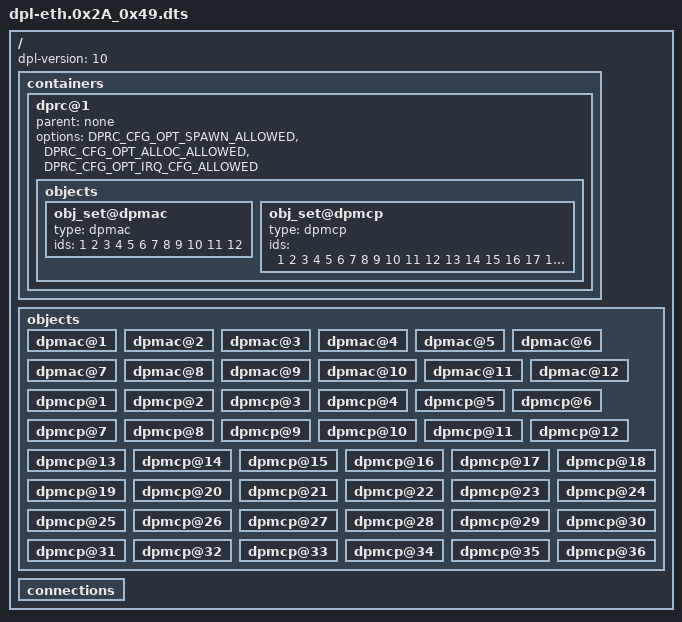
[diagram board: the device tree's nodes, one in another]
/*
 * Copyright 2016 Freescale Semiconductor, Inc.
 */

/dts-v1/;
/ {
	dpl-version = <10>;
	/*****************************************************************
	 * Containers
	 *****************************************************************/
	containers {
		dprc@1 {
			parent = "none";
			options = "DPRC_CFG_OPT_SPAWN_ALLOWED" , "DPRC_CFG_OPT_ALLOC_ALLOWED", "DPRC_CFG_OPT_IRQ_CFG_ALLOWED";

			objects {
				/* ------------- DPMACs --------------*/
				/* For SerDes 0x2a_49, 8 DPMACs are mapped
				 * on the 8 XFI ports and 4 DPMACs
				 * are mapped on the 4 SGMII ports of the PCIe
				 * Slot 4 riser card.
				 */
				obj_set@dpmac {
					type = "dpmac";
					ids = <1 2 3 4 5 6 7 8 9 10 11 12>;
				};

				/* ------------ DPMCPs --------------*/
				/* Ethernet DPMCPs:
				*  One for every DPNI, one for every DPMAC, then
				*  one more for DPIO.
				*
				*  Next: DPRC and restool, VFIO and possibly
				*  others from the kernel have DPMCP requirements.
				*  We'll just add a slack of 10 MCPs.
				*/
				obj_set@dpmcp {
					type = "dpmcp";
					ids = <1 2 3 4 5 6 7 8 9 10 11 12 13 14 15 16 17 18 19 20 21 22 23 24 25 26 27 28 29 30 31 32 33 34 35 36>;
				};
			};
		};
	};

	/*****************************************************************
	 * Objects
	 *****************************************************************/
	objects {
		/* ------------ DPMAC --------------*/
		dpmac@1 {
		};
		dpmac@2 {
		};
		dpmac@3 {
		};
		dpmac@4 {
		};
		dpmac@5 {
		};
		dpmac@6 {
		};
		dpmac@7 {
		};
		dpmac@8 {
		};
		dpmac@9 {
		};
		dpmac@10 {
		};
		dpmac@11 {
		};
		dpmac@12 {
		};

		/* ------------ DPMCP --------------*/
		dpmcp@1 {
		};
		dpmcp@2 {
		};
		dpmcp@3 {
		};
		dpmcp@4 {
		};
		dpmcp@5 {
		};
		dpmcp@6 {
		};
		dpmcp@7 {
		};
		dpmcp@8 {
		};
		dpmcp@9 {
		};
		dpmcp@10 {
		};
		dpmcp@11 {
		};
		dpmcp@12 {
		};
		dpmcp@13 {
		};
		dpmcp@14 {
		};
		dpmcp@15 {
		};
		dpmcp@16 {
		};
		dpmcp@17 {
		};
		dpmcp@18 {
		};
		dpmcp@19 {
		};
		dpmcp@20 {
		};
		dpmcp@21 {
		};
		dpmcp@22 {
		};
		dpmcp@23 {
		};
		dpmcp@24 {
		};
		dpmcp@25 {
		};
		dpmcp@26 {
		};
		dpmcp@27 {
		};
		dpmcp@28 {
		};
		dpmcp@29 {
		};
		dpmcp@30 {
		};
		dpmcp@31 {
		};
		dpmcp@32 {
		};
		dpmcp@33 {
		};
		dpmcp@34 {
		};
		dpmcp@35 {
		};
		dpmcp@36 {
		};
	};

	/*****************************************************************
	 * Connections
	 *****************************************************************/
	connections {
	};
};
